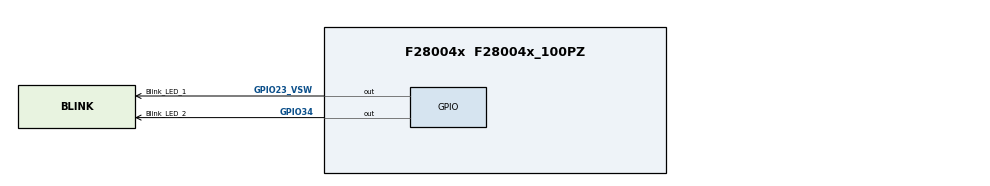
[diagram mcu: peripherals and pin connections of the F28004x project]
/**
 * @cliArgs --device "F28004x" --package "F28004x_100PZ" --part "F28004x_100PZ" --product "C2000WARE@3.00.00.00"
 * @versions {"tool":"1.9.0+1960","templates":null}
 */

/**
 * Import the modules used in this configuration.
 */
const cputimer  = scripting.addModule("/driverlib/cputimer.js", {}, false);
const cputimer1 = cputimer.addInstance();
const gpio      = scripting.addModule("/driverlib/gpio.js", {}, false);
const gpio1     = gpio.addInstance();
const gpio2     = gpio.addInstance();

/**
 * Write custom configuration values to the imported modules.
 */
cputimer1.$name                    = "Led_Toggle_Timer";
cputimer1.enableInterrupt          = true;
cputimer1.registerInterrupts       = true;
cputimer1.startTimer               = true;
cputimer1.timerPeriod              = 100000000;
cputimer1.timerInt.enableInterrupt = true;

gpio1.$name             = "Blink_LED_1";
gpio1.direction         = "GPIO_DIR_MODE_OUT";
gpio1.writeInitialValue = true;
gpio1.gpioPin.$assign   = "GPIO23_VSW";

gpio2.$name             = "Blink_LED_2";
gpio2.direction         = "GPIO_DIR_MODE_OUT";
gpio2.writeInitialValue = true;
gpio2.gpioPin.$assign   = "GPIO34";
